# ATtiny104 register map
Vendor: Atmel; File version: 1.0
CPU: other r0p0, little endian, no MPU, no FPU, 4 interrupt priority bits
Registers are 8-bit, read-write, reset 0x0 unless marked. A register's access mark holds for its fields unless they carry their own. Offsets are from the block's base; lines under a group give offsets from that group; [hi:lo] are bit positions; {n}, {i} and the like mark numbered series; 'fields as' and 'values as' point back to an identical list; <NAME> marks a mode.

## Memory map
0x00800000 PORTA blocks up to offset 0x17 — I/O Port
0x00800004 PORTB blocks up to offset 0x13 — I/O Port
0x00800008 USART size 0x7
0x0080000F EXINT size 0x7 — External Interrupts
0x00800017 AC blocks up to offset 0x9 — Analog Comparator
0x00800017 ADC blocks up to offset 0x7 — Analog-to-Digital Converter
0x00800022 TC0 size 0xE — Timer/Counter, 16-bit
0x00800031 WDT size 0x1 — Watchdog Timer
0x00800032 CPU blocks up to offset 0xE — CPU Registers

## Interrupts
0 RESET (CPU) — External Reset, Power-on Reset and Watchdog Reset
1 INT0 (CPU) — External Interrupt Request 0
2 PCINT0 (CPU) — Pin Change Interrupt Request 0
3 PCINT1 (CPU) — Pin Change Interrupt Request 1
4 TIM0_CAPT (CPU) — Timer/Counter0 Input Capture
5 TIM0_OVF (CPU) — Timer/Counter0 Overflow
6 TIM0_COMPA (CPU) — Timer/Counter Compare Match A
7 TIM0_COMPB (CPU) — Timer/Counter Compare Match B
8 ANA_COMP (CPU) — Analog Comparator
9 WDT (CPU) — Watchdog Time-out
10 VLM (CPU) — Vcc Voltage Level Monitor
11 ADC (CPU) — ADC Conversion complete
12 USART_RXS (CPU) — USART RX Start
13 USART_RXC (CPU) — USART RX Complete
14 USART_DRE (CPU) — USART Data register empty
15 USART_TXC (CPU) — USART Tx Complete

## AC — Analog Comparator
Base 0x00800017
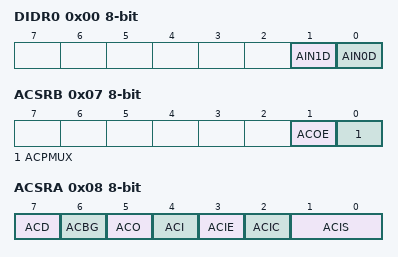
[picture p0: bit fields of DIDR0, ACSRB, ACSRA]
0x00 DIDR0
  [1] AIN1D — AIN1 Digital Input Disable
  [0] AIN0D — AIN0 Digital Input Disable
0x07 ACSRB — Analog Comparator Control And Status Register B
  [1] ACOE — Analog Comparator Output Enable
  [0] ACPMUX — Analog Comparator positive input selection bit
0x08 ACSRA — Analog Comparator Control And Status Register A
  [7] ACD — Analog Comparator Disable
  [6] ACBG — Analog Comparator Bandgap enable
  [5] ACO — Analog Compare Output
  [4] ACI — Analog Comparator Interrupt Flag
  [3] ACIE — Analog Comparator Interrupt Enable
  [2] ACIC — Analog Comparator Input Capture Enable
  [1:0] ACIS — Analog Comparator Interrupt Mode Select bits
    0=INTERRUPT_ON_TOGGLE; 2=INTERRUPT_ON_FALLING_EDGE; 3=INTERRUPT_ON_RISING_EDGE

## ADC — Analog-to-Digital Converter
Base 0x00800017
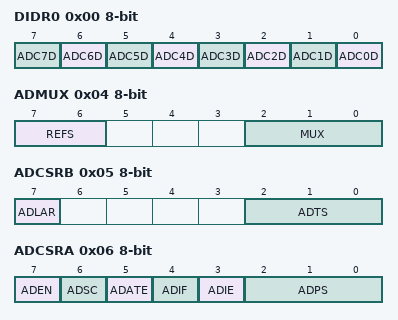
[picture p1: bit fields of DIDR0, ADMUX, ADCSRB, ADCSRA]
0x00 DIDR0 — Digital Input Disable Register
  [n] ADC{n}D (n=0..7) — ADC{n} Digital Input Disable
0x02 ADCL — ADC Data Register Low
0x03 ADCH — ADC Data Register High
0x04 ADMUX — The ADC multiplexer Selection Register
  [7:6] REFS — Analog Reference voltage Selection Bits
    0=VCC; 1=INTERNAL_1_1V_REFERENCE; 2=INTERNAL_2_2V_REFERENCE; 3=INTERNAL_4_3V_REFERENCE
  [2:0] MUX — Analog Channel Selection Bits
    {v}=ADC{v} (v=0..7)
0x05 ADCSRB — The ADC Control and Status register B
  [7] ADLAR — Left Adjustment for ADC Result Readout
  [2:0] ADTS — ADC Auto Trigger Source bits
    0=FREE_RUNNING_MODE; 1=ANALOG_COMPARATOR; 2=EXTERNAL_INTERRUPT_REQUEST_0; 3=TIMER_COUNTER0_COMPARE_MATCH_A; 4=TIMER_COUNTER0_OVERFLOW; 5=TIMER_COUNTER0_COMPARE_MATCH_B; 6=PIN_CHANGE_INTERRUPT_0_REQUEST; 7=TIMER_COUNTER0_CAPTURE_EVENT
0x06 ADCSRA — The ADC Control and Status register A
  [7] ADEN — ADC Enable
  [6] ADSC — ADC Start Conversion
  [5] ADATE — ADC Auto Trigger Enable
  [4] ADIF — ADC Interrupt Flag
  [3] ADIE — ADC Interrupt Enable
  [2:0] ADPS — ADC Prescaler Select Bits
    1=2; 2=4; 3=8; 4=16; 5=32; 6=64; 7=128

## CPU — CPU Registers
Base 0x00800032
0x00 NVMCSR — Non-Volatile Memory Control and Status Register
  [7] NVMBSY — Non-Volatile Memory Busy
0x01 NVMCMD — Non-Volatile Memory Command
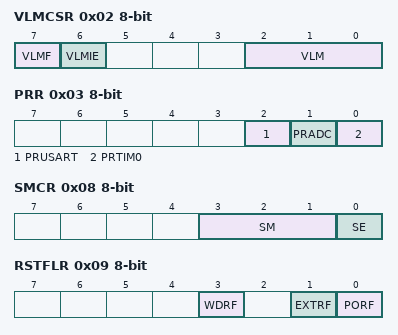
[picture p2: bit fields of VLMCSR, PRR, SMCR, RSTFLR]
0x02 VLMCSR — Vcc Level Monitoring Control and Status Register
  [7] VLMF — VLM Flag
  [6] VLMIE — VLM Interrupt Enable
  [2:0] VLM — Trigger Level of Voltage Level Monitor bits
0x03 PRR — Power Reduction Register
  [2] PRUSART — Power Reduction USART
  [1] PRADC — Power Reduction ADC
  [0] PRTIM0 — Power Reduction Timer/Counter0
0x04 CLKPSR — Clock Prescale Register
  [3:0] CLKPS — Clock Prescaler Select Bits
    0=1; 1=2; 2=4; 3=8; 4=16; 5=32; 6=64; 7=128; 8=256
0x05 CLKMSR — Clock Main Settings Register
  [1:0] CLKMS — Clock Main Select Bits
0x07 OSCCAL — Oscillator Calibration Value
0x08 SMCR — Sleep Mode Control Register
  [3:1] SM — Sleep Mode Select Bits
    0=IDLE; 1=ADC (ADC Noise Reduction); 2=PDOWN (Power Down); 4=STDBY (Standby)
  [0] SE — Sleep Enable
0x09 RSTFLR — Reset Flag Register
  [3] WDRF — Watchdog Reset Flag
  [1] EXTRF — External Reset Flag
  [0] PORF — Power-on Reset Flag
0x0A CCP — Configuration Change Protection
  [7:0] CCP — CCP signature
    216=IOREG (IO Register Protection); 231=SPM (SPM Instruction Protection)
0x0B SP 16-bit (reset mask 0xFF) — Stack Pointer
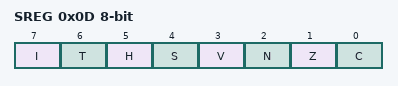
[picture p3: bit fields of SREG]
0x0D SREG — Status Register
  [7] I — Global Interrupt Enable
  [6] T — Bit Copy Storage
  [5] H — Half Carry Flag
  [4] S — Sign Bit
  [3] V — Two's Complement Overflow Flag
  [2] N — Negative Flag
  [1] Z — Zero Flag
  [0] C — Carry Flag
